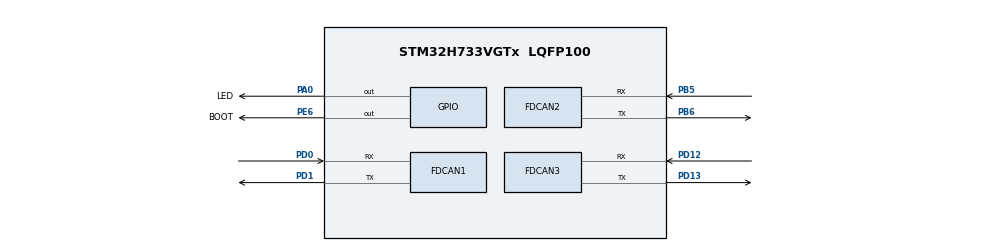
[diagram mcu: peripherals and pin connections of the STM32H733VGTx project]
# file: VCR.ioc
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CORTEX_M7.default_mode_Activation=0
FDCAN1.AutoRetransmission=ENABLE
FDCAN1.CalculateBaudRateNominal=1000000
FDCAN1.CalculateTimeBitNominal=1000
FDCAN1.CalculateTimeQuantumNominal=62.5
FDCAN1.DataSyncJumpWidth=1
FDCAN1.DataTimeSeg1=1
FDCAN1.DataTimeSeg2=1
FDCAN1.ExtFiltersNbr=1
FDCAN1.FrameFormat=FDCAN_FRAME_CLASSIC
FDCAN1.MessageRAMOffset=1280
FDCAN1.NominalPrescaler=6
FDCAN1.NominalSyncJumpWidth=3
FDCAN1.NominalTimeSeg1=12
FDCAN1.NominalTimeSeg2=3
FDCAN1.RxFifo0ElmtSize=FDCAN_DATA_BYTES_8
FDCAN1.RxFifo0ElmtsNbr=32
FDCAN1.RxFifo1ElmtSize=FDCAN_DATA_BYTES_8
FDCAN1.RxFifo1ElmtsNbr=0
FDCAN1.StdFiltersNbr=1
FDCAN1.TxElmtSize=FDCAN_DATA_BYTES_8
FDCAN1.TxFifoQueueElmtsNbr=32
FDCAN2.AutoRetransmission=ENABLE
FDCAN2.CalculateBaudRateNominal=1000000
FDCAN2.CalculateTimeBitNominal=1000
FDCAN2.CalculateTimeQuantumNominal=62.5
FDCAN2.DataPrescaler=3
FDCAN2.DataSyncJumpWidth=2
FDCAN2.DataTimeSeg1=5
FDCAN2.DataTimeSeg2=2
FDCAN2.ExtFiltersNbr=1
FDCAN2.FrameFormat=FDCAN_FRAME_FD_NO_BRS
FDCAN2.NominalPrescaler=6
FDCAN2.NominalSyncJumpWidth=2
FDCAN2.NominalTimeSeg1=13
FDCAN2.RxBufferSize=FDCAN_DATA_BYTES_64
FDCAN2.RxFifo0ElmtSize=FDCAN_DATA_BYTES_64
FDCAN2.RxFifo0ElmtsNbr=32
FDCAN2.RxFifo1ElmtSize=FDCAN_DATA_BYTES_64
FDCAN2.RxFifo1ElmtsNbr=0
FDCAN2.StdFiltersNbr=1
FDCAN2.TxElmtSize=FDCAN_DATA_BYTES_64
FDCAN2.TxFifoQueueElmtsNbr=32
FDCAN3.AutoRetransmission=ENABLE
FDCAN3.CalculateBaudRateNominal=500000
FDCAN3.CalculateTimeBitNominal=2000
FDCAN3.CalculateTimeQuantumNominal=125.0
FDCAN3.ExtFiltersNbr=1
FDCAN3.MessageRAMOffset=1920
FDCAN3.NominalPrescaler=12
FDCAN3.NominalSyncJumpWidth=3
FDCAN3.NominalTimeSeg1=12
FDCAN3.NominalTimeSeg2=3
FDCAN3.RxFifo0ElmtsNbr=32
FDCAN3.RxFifo1ElmtsNbr=0
FDCAN3.StdFiltersNbr=1
FDCAN3.TxFifoQueueElmtsNbr=32
FREERTOS.Tasks01=FDCanTx,24,512,StartFDCanTxTask,Default,NULL,Static,FDCanTXBuffer,FDCanTXControlBlock;CanRx,24,512,StartCanRxTask,Default,NULL,Static,CanRxBuffer,CanRxControlBlock;SxCanTxTask,40,512,StartSxCanTx,Default,NULL,Static,SxCanTxBuffer,SxCanTxControlBlock;InvCanTxTask,40,512,StartInvCanTx,Default,NULL,Static,InvCanTxBuffer,InvCanTxControlBlock;Task1Hz,24,512,StartTask1Hz,Default,NULL,Static,Task1HzBuffer,Task1HzControlBlock;Task1kHz,48,512,StartTask1kHz,Default,NULL,Static,Task1kHzBuffer,Task1kHzControlBlock
IWDG1.Reload=LSI_FREQUENCY / IWDG_PRESCALER / IWDG_RESET_FREQUENCY
Mcu.Family=STM32H7
Mcu.Name=STM32H733VGTx
Mcu.Package=LQFP100
Mcu.UserConstants=IWDG_RESET_FREQUENCY,5;IWDG_PRESCALER,4;LSI_FREQUENCY,32000
NVIC.FDCAN1_IT0_IRQn=true\:5\:0\:false\:false\:true\:true\:true\:true\:true
NVIC.FDCAN1_IT1_IRQn=true\:5\:0\:false\:false\:true\:true\:true\:true\:true
NVIC.FDCAN2_IT0_IRQn=true\:5\:0\:false\:false\:true\:true\:true\:true\:true
NVIC.FDCAN2_IT1_IRQn=true\:5\:0\:false\:false\:true\:true\:true\:true\:true
NVIC.FDCAN3_IT0_IRQn=true\:5\:0\:false\:false\:true\:true\:true\:true\:true
NVIC.FDCAN3_IT1_IRQn=true\:5\:0\:false\:false\:true\:true\:true\:true\:true
NVIC.PriorityGroup=NVIC_PRIORITYGROUP_4
NVIC.TIM6_DAC_IRQn=true\:15\:0\:false\:false\:true\:false\:false\:true\:true
NVIC.TimeBase=TIM6_DAC_IRQn
NVIC.TimeBaseIP=TIM6
PA0.GPIO_Label=LED
PA0.Signal=GPIO_Output
PA13(JTMS/SWDIO).GPIO_Label=SWDIO2
PA13(JTMS/SWDIO).Mode=Trace_Asynchronous_SW
PA13(JTMS/SWDIO).Signal=DEBUG_JTMS-SWDIO
PA14(JTCK/SWCLK).GPIO_Label=SWCLK2
PA14(JTCK/SWCLK).Mode=Trace_Asynchronous_SW
PA14(JTCK/SWCLK).Signal=DEBUG_JTCK-SWCLK
PB3(JTDO/TRACESWO).GPIO_Label=SWO2
PB3(JTDO/TRACESWO).Mode=Trace_Asynchronous_SW
PB3(JTDO/TRACESWO).Signal=DEBUG_JTDO-SWO
PB5.Mode=FDCAN_Activate
PB5.Signal=FDCAN2_RX
PB6.Mode=FDCAN_Activate
PB6.Signal=FDCAN2_TX
PD0.Mode=FDCAN_Activate
PD0.Signal=FDCAN1_RX
PD1.Mode=FDCAN_Activate
PD1.Signal=FDCAN1_TX
PD12.Mode=FDCAN_Activate
PD12.Signal=FDCAN3_RX
PD13.Mode=FDCAN_Activate
PD13.Signal=FDCAN3_TX
PE6.GPIO_Label=BOOT
PE6.Signal=GPIO_Output
PH0-OSC_IN.Mode=HSE-External-Oscillator
PH0-OSC_IN.Signal=RCC_OSC_IN
PH1-OSC_OUT.Mode=HSE-External-Oscillator
PH1-OSC_OUT.Signal=RCC_OSC_OUT
ProjectManager.HeapSize=0x200
ProjectManager.StackSize=0x400
ProjectManager.TargetToolchain=Makefile
RCC.ADCFreq_Value=96000000
RCC.APB1Freq_Value=128000000
RCC.APB2Freq_Value=128000000
RCC.APB3Freq_Value=128000000
RCC.APB4Freq_Value=128000000
RCC.CortexFreq_Value=512000000
RCC.D1PPRE=RCC_APB3_DIV2
RCC.D2PPRE1=RCC_APB1_DIV2
RCC.D2PPRE2=RCC_APB2_DIV2
RCC.D3PPRE=RCC_APB4_DIV2
RCC.DIVM1=1
RCC.DIVM2=1
RCC.DIVN1=64
RCC.DIVN2=24
RCC.DIVN3=24
RCC.DIVP1=1
RCC.FDCANCLockSelection=RCC_FDCANCLKSOURCE_PLL2
RCC.HCLKFreq_Value=256000000
RCC.HPRE=RCC_HCLK_DIV2
RCC.HSE_VALUE=8000000
RCC.PLLSourceVirtual=RCC_PLLSOURCE_HSE
RCC.SYSCLKFreq_VALUE=512000000
RCC.SYSCLKSource=RCC_SYSCLKSOURCE_PLLCLK
RCC.USBFreq_Value=256000000
VP_FREERTOS_VS_CMSIS_V2.Mode=CMSIS_V2
VP_IWDG1_VS_IWDG.Mode=IWDG_Activate
VP_MEMORYMAP_VS_MEMORYMAP.Mode=CurAppReg
VP_SYS_VS_tim6.Mode=TIM6
board=custom

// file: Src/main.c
/* USER CODE BEGIN Header */
/**
 ******************************************************************************
 * @file           : main.c
 * @brief          : Main program body
 ******************************************************************************
 * @attention
 *
 * Copyright (c) 2025 STMicroelectronics.
 * All rights reserved.
 *
 * This software is licensed under terms that can be found in the LICENSE file
 * in the root directory of this software component.
 * If no LICENSE file comes with this software, it is provided AS-IS.
 *
 ******************************************************************************
 */
/* USER CODE END Header */
#include "main.h"
#include "cmsis_os.h"

/* USER CODE BEGIN Includes */
#include "tasks.h"
#include "hw_error.h"
/* USER CODE END Includes */

typedef StaticTask_t osStaticThreadDef_t;

FDCAN_HandleTypeDef hfdcan1;
FDCAN_HandleTypeDef hfdcan2;
FDCAN_HandleTypeDef hfdcan3;

IWDG_HandleTypeDef hiwdg1;

void        SystemClock_Config(void);
void        PeriphCommonClock_Config(void);
static void MX_GPIO_Init(void);
static void MX_FDCAN1_Init(void);
static void MX_FDCAN2_Init(void);
static void MX_FDCAN3_Init(void);
static void MX_IWDG1_Init(void);

int main(void)
{
    /* USER CODE BEGIN 1 */
    tasks_preInit();
    /* USER CODE END 1 */

    /* MCU Configuration--------------------------------------------------------*/

    /* Reset of all peripherals, Initializes the Flash interface and the Systick. */
    HAL_Init();

    /* Configure the system clock */
    SystemClock_Config();

    /* Configure the peripherals common clocks */
    PeriphCommonClock_Config();

    /* Initialize all configured peripherals */
    MX_GPIO_Init();
    MX_FDCAN1_Init();
    MX_FDCAN2_Init();
    MX_FDCAN3_Init();
    MX_IWDG1_Init();

    /* Init scheduler */
    osKernelInitialize();

    /* USER CODE BEGIN RTOS_QUEUES */
    /* add queues, ... */
    tasks_init();
    /* USER CODE END RTOS_QUEUES */

    /* Create the thread(s) */
    /* USER CODE BEGIN RTOS_THREADS */
    /* add threads, ... */
    VCR_StartAllTasks();
    /* USER CODE END RTOS_THREADS */

    /* Start scheduler */
    osKernelStart();

    /* We should never get here as control is now taken by the scheduler */

    /* Infinite loop */
    while (1)
    {

    }
}

void SystemClock_Config(void)
{
    RCC_OscInitTypeDef RCC_OscInitStruct = { 0 };
    RCC_ClkInitTypeDef RCC_ClkInitStruct = { 0 };

    /** Supply configuration update enable
     */
    HAL_PWREx_ConfigSupply(PWR_LDO_SUPPLY);

    /** Configure the main internal regulator output voltage
     */
    __HAL_PWR_VOLTAGESCALING_CONFIG(PWR_REGULATOR_VOLTAGE_SCALE0);

    while (!__HAL_PWR_GET_FLAG(PWR_FLAG_VOSRDY))
    {
    }

    /** Initializes the RCC Oscillators according to the specified parameters
     * in the RCC_OscInitTypeDef structure.
     */
    RCC_OscInitStruct.OscillatorType = RCC_OSCILLATORTYPE_LSI | RCC_OSCILLATORTYPE_HSE;
    RCC_OscInitStruct.HSEState       = RCC_HSE_ON;
    RCC_OscInitStruct.LSIState       = RCC_LSI_ON;
    RCC_OscInitStruct.PLL.PLLState   = RCC_PLL_ON;
    RCC_OscInitStruct.PLL.PLLSource  = RCC_PLLSOURCE_HSE;
    RCC_OscInitStruct.PLL.PLLM       = 1;
    RCC_OscInitStruct.PLL.PLLN       = 64;
    RCC_OscInitStruct.PLL.PLLP       = 1;
    RCC_OscInitStruct.PLL.PLLQ       = 2;
    RCC_OscInitStruct.PLL.PLLR       = 2;
    RCC_OscInitStruct.PLL.PLLRGE     = RCC_PLL1VCIRANGE_3;
    RCC_OscInitStruct.PLL.PLLVCOSEL  = RCC_PLL1VCOWIDE;
    RCC_OscInitStruct.PLL.PLLFRACN   = 0;
    if (HAL_RCC_OscConfig(&RCC_OscInitStruct) != HAL_OK)
    {
        Error_Handler();
    }

    /** Initializes the CPU, AHB and APB buses clocks
     */
    RCC_ClkInitStruct.ClockType = RCC_CLOCKTYPE_HCLK | RCC_CLOCKTYPE_SYSCLK | RCC_CLOCKTYPE_PCLK1 |
                                  RCC_CLOCKTYPE_PCLK2 | RCC_CLOCKTYPE_D3PCLK1 | RCC_CLOCKTYPE_D1PCLK1;
    RCC_ClkInitStruct.SYSCLKSource   = RCC_SYSCLKSOURCE_PLLCLK;
    RCC_ClkInitStruct.SYSCLKDivider  = RCC_SYSCLK_DIV1;
    RCC_ClkInitStruct.AHBCLKDivider  = RCC_HCLK_DIV2;
    RCC_ClkInitStruct.APB3CLKDivider = RCC_APB3_DIV2;
    RCC_ClkInitStruct.APB1CLKDivider = RCC_APB1_DIV2;
    RCC_ClkInitStruct.APB2CLKDivider = RCC_APB2_DIV2;
    RCC_ClkInitStruct.APB4CLKDivider = RCC_APB4_DIV2;

    if (HAL_RCC_ClockConfig(&RCC_ClkInitStruct, FLASH_LATENCY_3) != HAL_OK)
    {
        Error_Handler();
    }
}

void PeriphCommonClock_Config(void)
{
    RCC_PeriphCLKInitTypeDef PeriphClkInitStruct = { 0 };

    /** Initializes the peripherals clock
     */
    PeriphClkInitStruct.PeriphClockSelection = RCC_PERIPHCLK_FDCAN;
    PeriphClkInitStruct.PLL2.PLL2M           = 1;
    PeriphClkInitStruct.PLL2.PLL2N           = 24;
    PeriphClkInitStruct.PLL2.PLL2P           = 2;
    PeriphClkInitStruct.PLL2.PLL2Q           = 2;
    PeriphClkInitStruct.PLL2.PLL2R           = 2;
    PeriphClkInitStruct.PLL2.PLL2RGE         = RCC_PLL2VCIRANGE_3;
    PeriphClkInitStruct.PLL2.PLL2VCOSEL      = RCC_PLL2VCOWIDE;
    PeriphClkInitStruct.PLL2.PLL2FRACN       = 0;
    PeriphClkInitStruct.FdcanClockSelection  = RCC_FDCANCLKSOURCE_PLL2;
    if (HAL_RCCEx_PeriphCLKConfig(&PeriphClkInitStruct) != HAL_OK)
    {
        Error_Handler();
    }
}

static void MX_FDCAN1_Init(void)
{

    hfdcan1.Instance                  = FDCAN1;
    hfdcan1.Init.FrameFormat          = FDCAN_FRAME_CLASSIC;
    hfdcan1.Init.Mode                 = FDCAN_MODE_NORMAL;
    hfdcan1.Init.AutoRetransmission   = ENABLE;
    hfdcan1.Init.TransmitPause        = DISABLE;
    hfdcan1.Init.ProtocolException    = DISABLE;
    hfdcan1.Init.NominalPrescaler     = 6;
    hfdcan1.Init.NominalSyncJumpWidth = 3;
    hfdcan1.Init.NominalTimeSeg1      = 12;
    hfdcan1.Init.NominalTimeSeg2      = 3;
    hfdcan1.Init.DataPrescaler        = 1;
    hfdcan1.Init.DataSyncJumpWidth    = 1;
    hfdcan1.Init.DataTimeSeg1         = 1;
    hfdcan1.Init.DataTimeSeg2         = 1;
    hfdcan1.Init.MessageRAMOffset     = 1280;
    hfdcan1.Init.StdFiltersNbr        = 1;
    hfdcan1.Init.ExtFiltersNbr        = 1;
    hfdcan1.Init.RxFifo0ElmtsNbr      = 32;
    hfdcan1.Init.RxFifo0ElmtSize      = FDCAN_DATA_BYTES_8;
    hfdcan1.Init.RxFifo1ElmtsNbr      = 0;
    hfdcan1.Init.RxFifo1ElmtSize      = FDCAN_DATA_BYTES_8;
    hfdcan1.Init.RxBuffersNbr         = 0;
    hfdcan1.Init.RxBufferSize         = FDCAN_DATA_BYTES_8;
    hfdcan1.Init.TxEventsNbr          = 0;
    hfdcan1.Init.TxBuffersNbr         = 0;
    hfdcan1.Init.TxFifoQueueElmtsNbr  = 32;
    hfdcan1.Init.TxFifoQueueMode      = FDCAN_TX_FIFO_OPERATION;
    hfdcan1.Init.TxElmtSize           = FDCAN_DATA_BYTES_8;
    if (HAL_FDCAN_Init(&hfdcan1) != HAL_OK)
    {
        Error_Handler();
    }
}

static void MX_FDCAN2_Init(void)
{

    hfdcan2.Instance                  = FDCAN2;
    hfdcan2.Init.FrameFormat          = FDCAN_FRAME_FD_NO_BRS;
    hfdcan2.Init.Mode                 = FDCAN_MODE_NORMAL;
    hfdcan2.Init.AutoRetransmission   = ENABLE;
    hfdcan2.Init.TransmitPause        = DISABLE;
    hfdcan2.Init.ProtocolException    = DISABLE;
    hfdcan2.Init.NominalPrescaler     = 6;
    hfdcan2.Init.NominalSyncJumpWidth = 2;
    hfdcan2.Init.NominalTimeSeg1      = 13;
    hfdcan2.Init.NominalTimeSeg2      = 2;
    hfdcan2.Init.DataPrescaler        = 3;
    hfdcan2.Init.DataSyncJumpWidth    = 2;
    hfdcan2.Init.DataTimeSeg1         = 5;
    hfdcan2.Init.DataTimeSeg2         = 2;
    hfdcan2.Init.MessageRAMOffset     = 0;
    hfdcan2.Init.StdFiltersNbr        = 1;
    hfdcan2.Init.ExtFiltersNbr        = 1;
    hfdcan2.Init.RxFifo0ElmtsNbr      = 32;
    hfdcan2.Init.RxFifo0ElmtSize      = FDCAN_DATA_BYTES_64;
    hfdcan2.Init.RxFifo1ElmtsNbr      = 0;
    hfdcan2.Init.RxFifo1ElmtSize      = FDCAN_DATA_BYTES_64;
    hfdcan2.Init.RxBuffersNbr         = 0;
    hfdcan2.Init.RxBufferSize         = FDCAN_DATA_BYTES_64;
    hfdcan2.Init.TxEventsNbr          = 0;
    hfdcan2.Init.TxBuffersNbr         = 0;
    hfdcan2.Init.TxFifoQueueElmtsNbr  = 32;
    hfdcan2.Init.TxFifoQueueMode      = FDCAN_TX_FIFO_OPERATION;
    hfdcan2.Init.TxElmtSize           = FDCAN_DATA_BYTES_64;
    if (HAL_FDCAN_Init(&hfdcan2) != HAL_OK)
    {
        Error_Handler();
    }
}

static void MX_FDCAN3_Init(void)
{

    hfdcan3.Instance                  = FDCAN3;
    hfdcan3.Init.FrameFormat          = FDCAN_FRAME_CLASSIC;
    hfdcan3.Init.Mode                 = FDCAN_MODE_NORMAL;
    hfdcan3.Init.AutoRetransmission   = ENABLE;
    hfdcan3.Init.TransmitPause        = DISABLE;
    hfdcan3.Init.ProtocolException    = DISABLE;
    hfdcan3.Init.NominalPrescaler     = 12;
    hfdcan3.Init.NominalSyncJumpWidth = 3;
    hfdcan3.Init.NominalTimeSeg1      = 12;
    hfdcan3.Init.NominalTimeSeg2      = 3;
    hfdcan3.Init.DataPrescaler        = 1;
    hfdcan3.Init.DataSyncJumpWidth    = 1;
    hfdcan3.Init.DataTimeSeg1         = 1;
    hfdcan3.Init.DataTimeSeg2         = 1;
    hfdcan3.Init.MessageRAMOffset     = 1920;
    hfdcan3.Init.StdFiltersNbr        = 1;
    hfdcan3.Init.ExtFiltersNbr        = 1;
    hfdcan3.Init.RxFifo0ElmtsNbr      = 32;
    hfdcan3.Init.RxFifo0ElmtSize      = FDCAN_DATA_BYTES_8;
    hfdcan3.Init.RxFifo1ElmtsNbr      = 0;
    hfdcan3.Init.RxFifo1ElmtSize      = FDCAN_DATA_BYTES_8;
    hfdcan3.Init.RxBuffersNbr         = 0;
    hfdcan3.Init.RxBufferSize         = FDCAN_DATA_BYTES_8;
    hfdcan3.Init.TxEventsNbr          = 0;
    hfdcan3.Init.TxBuffersNbr         = 0;
    hfdcan3.Init.TxFifoQueueElmtsNbr  = 32;
    hfdcan3.Init.TxFifoQueueMode      = FDCAN_TX_FIFO_OPERATION;
    hfdcan3.Init.TxElmtSize           = FDCAN_DATA_BYTES_8;
    if (HAL_FDCAN_Init(&hfdcan3) != HAL_OK)
    {
        Error_Handler();
    }
}

static void MX_IWDG1_Init(void)
{

    hiwdg1.Instance       = IWDG1;
    hiwdg1.Init.Prescaler = IWDG_PRESCALER_4;
    hiwdg1.Init.Window    = 4095;
    hiwdg1.Init.Reload    = LSI_FREQUENCY / IWDG_PRESCALER / IWDG_RESET_FREQUENCY;
    if (HAL_IWDG_Init(&hiwdg1) != HAL_OK)
    {
        Error_Handler();
    }
}

static void MX_GPIO_Init(void)
{
    GPIO_InitTypeDef GPIO_InitStruct = { 0 };

    /* GPIO Ports Clock Enable */
    __HAL_RCC_GPIOE_CLK_ENABLE();
    __HAL_RCC_GPIOH_CLK_ENABLE();
    __HAL_RCC_GPIOA_CLK_ENABLE();
    __HAL_RCC_GPIOD_CLK_ENABLE();
    __HAL_RCC_GPIOB_CLK_ENABLE();

    /*Configure GPIO pin Output Level */
    HAL_GPIO_WritePin(BOOT_GPIO_Port, BOOT_Pin, GPIO_PIN_RESET);

    /*Configure GPIO pin Output Level */
    HAL_GPIO_WritePin(LED_GPIO_Port, LED_Pin, GPIO_PIN_RESET);

    /*Configure GPIO pin : BOOT_Pin */
    GPIO_InitStruct.Pin   = BOOT_Pin;
    GPIO_InitStruct.Mode  = GPIO_MODE_OUTPUT_PP;
    GPIO_InitStruct.Pull  = GPIO_NOPULL;
    GPIO_InitStruct.Speed = GPIO_SPEED_FREQ_LOW;
    HAL_GPIO_Init(BOOT_GPIO_Port, &GPIO_InitStruct);

    /*Configure GPIO pin : LED_Pin */
    GPIO_InitStruct.Pin   = LED_Pin;
    GPIO_InitStruct.Mode  = GPIO_MODE_OUTPUT_PP;
    GPIO_InitStruct.Pull  = GPIO_NOPULL;
    GPIO_InitStruct.Speed = GPIO_SPEED_FREQ_LOW;
    HAL_GPIO_Init(LED_GPIO_Port, &GPIO_InitStruct);

}

void StartFDCanTxTask(void *argument)
{
}

void StartCanRxTask(void *argument)
{
}

void StartSxCanTx(void *argument)
{
}

void StartInvCanTx(void *argument)
{
}

void StartTask1Hz(void *argument)
{
}

void StartTask1kHz(void *argument)
{
}

void HAL_TIM_PeriodElapsedCallback(TIM_HandleTypeDef *htim)
{
    if (htim->Instance == TIM6)
    {
        HAL_IncTick();
    }
}

void Error_Handler(void)
{
    __disable_irq();
    while (1)
    {
    }
}
